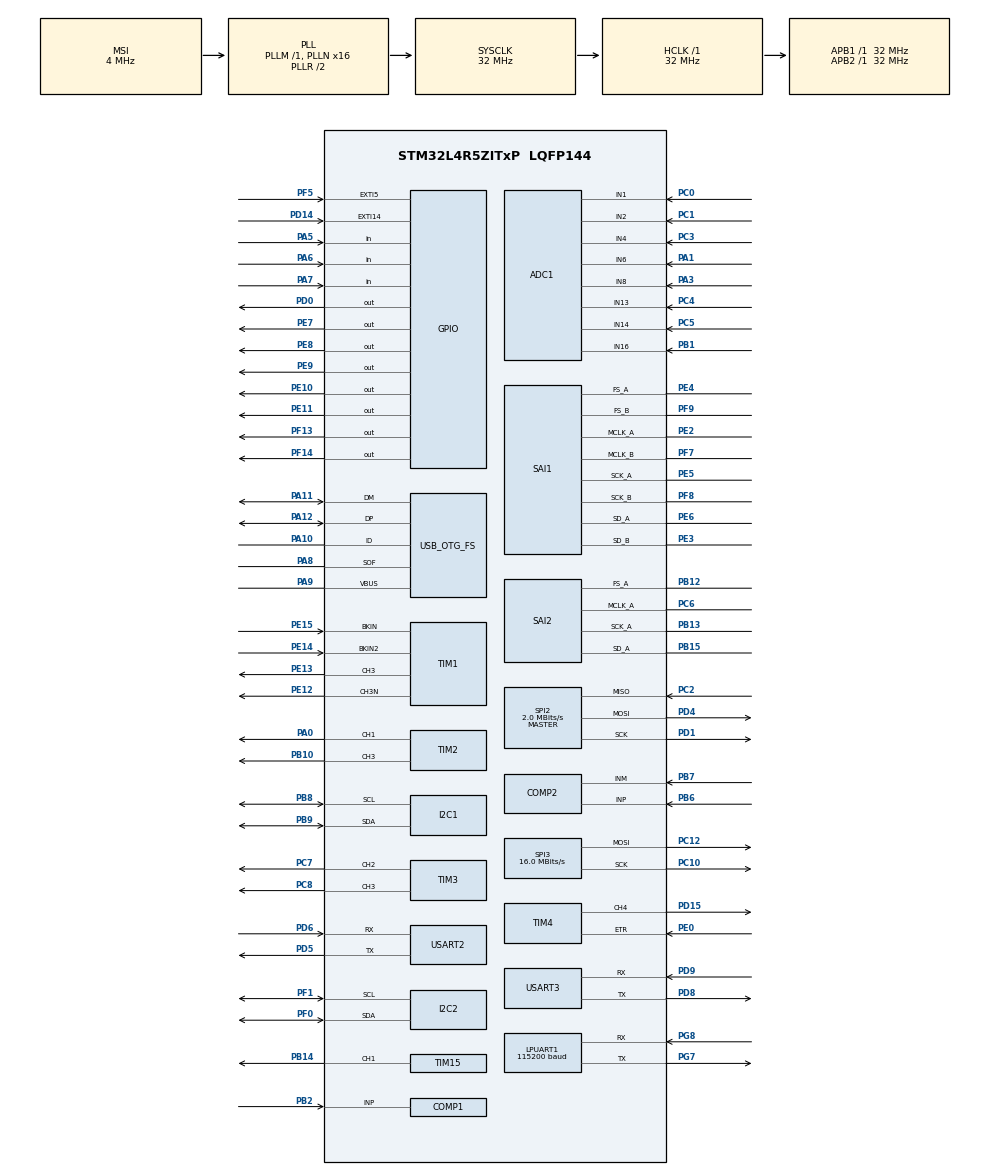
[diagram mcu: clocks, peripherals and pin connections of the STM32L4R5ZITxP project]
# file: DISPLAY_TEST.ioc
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ADC1.Channel-0\#ChannelRegularConversion=ADC_CHANNEL_1
ADC1.NbrOfConversionFlag=1
ADC1.OffsetNumber-0\#ChannelRegularConversion=ADC_OFFSET_NONE
ADC1.Rank-0\#ChannelRegularConversion=1
ADC1.SamplingTime-0\#ChannelRegularConversion=ADC_SAMPLETIME_2CYCLES_5
ADC1.master=1
I2C1.Timing=0x00707CBB
I2C2.Timing=0x00707CBB
LPUART1.BaudRate=115200
LPUART1.WordLength=UART_WORDLENGTH_8B
Mcu.Family=STM32L4
Mcu.Name=STM32L4R5ZITxP
Mcu.Package=LQFP144
NVIC.EXTI15_10_IRQn=true\:0\:0\:false\:false\:true\:true\:true\:true
NVIC.EXTI9_5_IRQn=true\:0\:0\:false\:false\:true\:true\:true\:true
NVIC.PriorityGroup=NVIC_PRIORITYGROUP_4
NVIC.TIM1_TRG_COM_TIM17_IRQn=true\:0\:0\:false\:false\:true\:true\:true\:true
PA0.Signal=S_TIM2_CH1
PA1.Signal=ADCx_IN6
PA10.Mode=OTG/Dual_Role_Device
PA10.Signal=USB_OTG_FS_ID
PA11.Mode=OTG/Dual_Role_Device
PA11.Signal=USB_OTG_FS_DM
PA12.Mode=OTG/Dual_Role_Device
PA12.Signal=USB_OTG_FS_DP
PA13\ (JTMS/SWDIO).Mode=Serial_Wire
PA13\ (JTMS/SWDIO).Signal=SYS_JTMS-SWDIO
PA14\ (JTCK/SWCLK).Mode=Serial_Wire
PA14\ (JTCK/SWCLK).Signal=SYS_JTCK-SWCLK
PA3.Signal=ADCx_IN8
PA4.Signal=SPI1_NSS
PA5.GPIO_PuPd=GPIO_PULLUP
PA5.Signal=GPIO_Input
PA6.GPIO_PuPd=GPIO_PULLUP
PA6.Signal=GPIO_Input
PA7.GPIO_PuPd=GPIO_PULLUP
PA7.Signal=GPIO_Input
PA8.Mode=Activate_SOF_FS
PA8.Signal=USB_OTG_FS_SOF
PA9.Mode=Activate_VBUS
PA9.Signal=USB_OTG_FS_VBUS
PB1.Signal=ADCx_IN16
PB10.Signal=S_TIM2_CH3
PB12.Mode=SAI_A_MasterWithClock
PB12.Signal=SAI2_FS_A
PB13.Mode=SAI_A_MasterWithClock
PB13.Signal=SAI2_SCK_A
PB14.Signal=S_TIM15_CH1
PB15.Mode=SAI_A_MasterWithClock
PB15.Signal=SAI2_SD_A
PB2.Mode=INP
PB2.Signal=COMP1_INP
PB6.Mode=INP
PB6.Signal=COMP2_INP
PB7.Mode=INM
PB7.Signal=COMP2_INM
PB8.GPIO_Pu=GPIO_PULLUP
PB8.Mode=I2C
PB8.Signal=I2C1_SCL
PB9.GPIO_Pu=GPIO_PULLUP
PB9.Mode=I2C
PB9.Signal=I2C1_SDA
PC0.Signal=ADCx_IN1
PC1.Signal=ADCx_IN2
PC10.Mode=TX_Only_Simplex_Unidirect_Master
PC10.Signal=SPI3_SCK
PC11.Signal=SPI3_MISO
PC12.Mode=TX_Only_Simplex_Unidirect_Master
PC12.Signal=SPI3_MOSI
PC13.Mode=SYS_WakeUp1
PC13.Signal=SYS_WKUP2
PC14-OSC32_IN\ (PC14).Mode=LSE-External-Oscillator
PC14-OSC32_IN\ (PC14).Signal=RCC_OSC32_IN
PC15-OSC32_OUT\ (PC15).Mode=LSE-External-Oscillator
PC15-OSC32_OUT\ (PC15).Signal=RCC_OSC32_OUT
PC2.Mode=Full_Duplex_Master
PC2.Signal=SPI2_MISO
PC3.Signal=ADCx_IN4
PC4.Signal=ADCx_IN13
PC5.Signal=ADCx_IN14
PC6.Mode=SAI_A_MasterWithClock
PC6.Signal=SAI2_MCLK_A
PC7.Signal=S_TIM3_CH2
PC8.Signal=S_TIM3_CH3
PC9.Signal=SDMMC1_D1
PD0.PinState=GPIO_PIN_SET
PD0.Signal=GPIO_Output
PD1.Mode=Full_Duplex_Master
PD1.Signal=SPI2_SCK
PD14.GPIO_ModeDefaultEXTI=GPIO_MODE_IT_FALLING
PD14.GPIO_PuPd=GPIO_PULLUP
PD14.Signal=GPXTI14
PD15.Signal=S_TIM4_CH4
PD2.Signal=SDMMC1_CMD
PD4.Mode=Full_Duplex_Master
PD4.Signal=SPI2_MOSI
PD5.Mode=Asynchronous
PD5.Signal=USART2_TX
PD6.Mode=Asynchronous
PD6.Signal=USART2_RX
PD8.Mode=Asynchronous
PD8.Signal=USART3_TX
PD9.Mode=Asynchronous
PD9.Signal=USART3_RX
PE0.Signal=S_TIM4_ETR
PE10.GPIO_PuPd=GPIO_PULLUP
PE10.Signal=GPIO_Output
PE11.GPIO_ModeDefaultOutputPP=GPIO_MODE_OUTPUT_OD
PE11.GPIO_PuPd=GPIO_NOPULL
PE11.PinState=GPIO_PIN_RESET
PE11.Signal=GPIO_Output
PE12.Mode=PWM Generation3 CH3 CH3N
PE12.Signal=TIM1_CH3N
PE13.Signal=S_TIM1_CH3
PE14.Mode=Activate-Break-Input-2
PE14.Signal=TIM1_BKIN2
PE15.Mode=Activate-Break-Input
PE15.Signal=TIM1_BKIN
PE2.Mode=SAI_A_MasterWithClock
PE2.Signal=SAI1_MCLK_A
PE3.Mode=SAI_B_MasterWithClock
PE3.Signal=SAI1_SD_B
PE4.Mode=SAI_A_MasterWithClock
PE4.Signal=SAI1_FS_A
PE5.Mode=SAI_A_MasterWithClock
PE5.Signal=SAI1_SCK_A
PE6.Mode=SAI_A_MasterWithClock
PE6.Signal=SAI1_SD_A
PE7.GPIO_PuPd=GPIO_PULLUP
PE7.Signal=GPIO_Output
PE8.GPIO_PuPd=GPIO_PULLUP
PE8.Signal=GPIO_Output
PE9.GPIO_ModeDefaultOutputPP=GPIO_MODE_OUTPUT_OD
PE9.GPIO_PuPd=GPIO_NOPULL
PE9.PinState=GPIO_PIN_RESET
PE9.Signal=GPIO_Output
PF0.GPIO_Pu=GPIO_NOPULL
PF0.Mode=I2C
PF0.Signal=I2C2_SDA
PF1.GPIO_Pu=GPIO_NOPULL
PF1.Mode=I2C
PF1.Signal=I2C2_SCL
PF13.GPIO_ModeDefaultOutputPP=GPIO_MODE_OUTPUT_OD
PF13.GPIO_PuPd=GPIO_NOPULL
PF13.PinState=GPIO_PIN_RESET
PF13.Signal=GPIO_Output
PF14.GPIO_ModeDefaultOutputPP=GPIO_MODE_OUTPUT_OD
PF14.GPIO_PuPd=GPIO_NOPULL
PF14.PinState=GPIO_PIN_RESET
PF14.Signal=GPIO_Output
PF2.GPIO_Pu=GPIO_PULLUP
PF2.Signal=I2C2_SMBA
PF5.Signal=GPXTI5
PF7.Mode=SAI_B_MasterWithClock
PF7.Signal=SAI1_MCLK_B
PF8.Mode=SAI_B_MasterWithClock
PF8.Signal=SAI1_SCK_B
PF9.Mode=SAI_B_MasterWithClock
PF9.Signal=SAI1_FS_B
PG7.Mode=Asynchronous
PG7.Signal=LPUART1_TX
PG8.Mode=Asynchronous
PG8.Signal=LPUART1_RX
PH0-OSC_IN\ (PH0).Mode=HSE-External-Oscillator
PH0-OSC_IN\ (PH0).Signal=RCC_OSC_IN
PH1-OSC_OUT\ (PH1).Mode=HSE-External-Oscillator
PH1-OSC_OUT\ (PH1).Signal=RCC_OSC_OUT
ProjectManager.HeapSize=0x200
ProjectManager.StackSize=0x400
ProjectManager.TargetToolchain=STM32CubeIDE
RCC.ADCFreq_Value=48000000
RCC.AHBFreq_Value=32000000
RCC.APB1Freq_Value=32000000
RCC.APB1TimFreq_Value=32000000
RCC.APB2Freq_Value=32000000
RCC.APB2TimFreq_Value=32000000
RCC.CortexFreq_Value=32000000
RCC.HCLKFreq_Value=32000000
RCC.HSE_VALUE=8000000
RCC.HSI48_VALUE=48000000
RCC.HSI_VALUE=16000000
RCC.MSI_VALUE=4000000
RCC.PLLN=16
RCC.PLLSAI1N=24
RCC.SYSCLKFreq_VALUE=32000000
RCC.SYSCLKSource=RCC_SYSCLKSOURCE_PLLCLK
RCC.USBFreq_Value=48000000
RCC.VCOOutputFreq_Value=64000000
SAI1.InitProtocol-SAI_A_MasterWithClock=Enable
SAI1.Instance-SAI_A_MasterWithClock=SAI$Index_Block_A
SAI1.Instance-SAI_B_MasterWithClock=SAI$Index_Block_B
SAI1.MClockEnable-SAI_A_MasterWithClock=SAI_MASTERCLOCK_ENABLE
SAI1.MClockEnable-SAI_B_MasterWithClock=SAI_MASTERCLOCK_ENABLE
SAI1.Synchro-SAI_A_MasterWithClock=SAI_ASYNCHRONOUS
SAI1.Synchro-SAI_B_MasterWithClock=SAI_ASYNCHRONOUS
SAI1.VirtualMode-SAI_A_MasterWithClock=VM_MASTER
SAI1.VirtualMode-SAI_B_MasterWithClock=VM_MASTER
SAI1.VirtualProtocol-SAI_A_BASIC=VM_BASIC_PROTOCOL
SAI2.Instance-SAI_A_MasterWithClock=SAI$Index_Block_A
SAI2.MClockEnable-SAI_A_MasterWithClock=SAI_MASTERCLOCK_ENABLE
SAI2.Synchro-SAI_A_MasterWithClock=SAI_ASYNCHRONOUS
SAI2.VirtualMode-SAI_A_MasterWithClock=VM_MASTER
SH.ADCx_IN1.0=ADC1_IN1,IN1-Single-Ended
SH.ADCx_IN13.0=ADC1_IN13,IN13-Single-Ended
SH.ADCx_IN14.0=ADC1_IN14,IN14-Single-Ended
SH.ADCx_IN16.0=ADC1_IN16,IN16-Single-Ended
SH.ADCx_IN2.0=ADC1_IN2,IN2-Single-Ended
SH.ADCx_IN4.0=ADC1_IN4,IN4-Single-Ended
SH.ADCx_IN6.0=ADC1_IN6,IN6-Single-Ended
SH.ADCx_IN8.0=ADC1_IN8,IN8-Single-Ended
SH.S_TIM15_CH1.0=TIM15_CH1,PWM Generation1 CH1
SH.S_TIM1_CH3.0=TIM1_CH3,PWM Generation3 CH3 CH3N
SH.S_TIM2_CH1.0=TIM2_CH1,PWM Generation1 CH1
SH.S_TIM2_CH3.0=TIM2_CH3,PWM Generation3 CH3
SH.S_TIM3_CH2.0=TIM3_CH2,PWM Generation2 CH2
SH.S_TIM3_CH3.0=TIM3_CH3,PWM Generation3 CH3
SH.S_TIM4_CH4.0=TIM4_CH4,PWM Generation4 CH4
SH.S_TIM4_ETR.0=TIM4_ETR,ETR-as-clearing-source
SPI2.BaudRatePrescaler=SPI_BAUDRATEPRESCALER_16
SPI2.CalculateBaudRate=2.0 MBits/s
SPI2.DataSize=SPI_DATASIZE_8BIT
SPI2.Direction=SPI_DIRECTION_2LINES
SPI2.Mode=SPI_MODE_MASTER
SPI2.VirtualType=VM_MASTER
SPI3.CalculateBaudRate=16.0 MBits/s
SPI3.DataSize=SPI_DATASIZE_8BIT
SPI3.Direction=SPI_DIRECTION_2LINES
SPI3.Mode=SPI_MODE_MASTER
SPI3.VirtualType=VM_MASTER
TIM1.Channel-PWM\ Generation3\ CH3\ CH3N=TIM_CHANNEL_3
TIM15.Channel-PWM\ Generation1\ CH1=TIM_CHANNEL_1
TIM17.Channel=TIM_CHANNEL_1
TIM17.Prescaler=2441
TIM2.Channel-PWM\ Generation1\ CH1=TIM_CHANNEL_1
TIM2.Channel-PWM\ Generation3\ CH3=TIM_CHANNEL_3
TIM3.Channel-PWM\ Generation2\ CH2=TIM_CHANNEL_2
TIM3.Channel-PWM\ Generation3\ CH3=TIM_CHANNEL_3
TIM4.Channel-PWM\ Generation4\ CH4=TIM_CHANNEL_4
USART2.VirtualMode-Asynchronous=VM_ASYNC
USART3.VirtualMode-Asynchronous=VM_ASYNC
VP_COMP1_VS_VREFINT.Mode=VREFINT
VP_SAI1_VP_$IpInstance_SAIA_SAI_BASIC.Mode=SAI_A_BASIC
VP_TIM17_VS_ClockSourceINT.Mode=Enable_Timer
VP_TIM17_VS_no_output1.Mode=Output Compare1 No Output
VP_TIM3_VS_ClockSourceINT.Mode=Internal
board=NUCLEO-L4R5ZI-P

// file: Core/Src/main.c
/* USER CODE BEGIN Header */
/**
 ******************************************************************************
 * @file           : main.c
 * @brief          : Main program body
 ******************************************************************************
 * @attention
 *
 * Copyright (c) 2024 STMicroelectronics.
 * All rights reserved.
 *
 * This software is licensed under terms that can be found in the LICENSE file
 * in the root directory of this software component.
 * If no LICENSE file comes with this software, it is provided AS-IS.
 *
 ******************************************************************************
 */
/* USER CODE END Header */
#include "main.h"

/* USER CODE BEGIN Includes */
#include "TempHumSensor.h"
#include "lcd.h"
#include "lora_sx1276.h"
#include "strain.h"
/* USER CODE END Includes */

ADC_HandleTypeDef hadc1;

COMP_HandleTypeDef hcomp1;
COMP_HandleTypeDef hcomp2;

I2C_HandleTypeDef hi2c1;
I2C_HandleTypeDef hi2c2;

UART_HandleTypeDef hlpuart1;
UART_HandleTypeDef huart2;
UART_HandleTypeDef huart3;

SAI_HandleTypeDef hsai_BlockB1;
SAI_HandleTypeDef hsai_BlockA1;
SAI_HandleTypeDef hsai_BlockA2;

SPI_HandleTypeDef hspi2;
SPI_HandleTypeDef hspi3;

TIM_HandleTypeDef htim1;
TIM_HandleTypeDef htim2;
TIM_HandleTypeDef htim3;
TIM_HandleTypeDef htim4;
TIM_HandleTypeDef htim15;
TIM_HandleTypeDef htim17;

/* USER CODE BEGIN PV */
lora_sx1276 lora;
uint8_t DISPLAY_TIMER_TRIGGERED;
// When 'D' is selected
uint8_t KeyPadSelect = 0;
uint8_t LoRaRecieve = 0;
extern uint8_t age;

// struct gps_data {
//	float longitude;
//	float latitude;
// };

struct arm_to_base {
  //	struct gps_data data;
  float velocity;
  float distance;
  int heartrate;
  int steps;
};

// Or were we sending height and weight over LoRa???
struct base_to_arm {
  uint8_t buzz;
};
/* USER CODE END PV */

void SystemClock_Config(void);
void PeriphCommonClock_Config(void);
static void MX_GPIO_Init(void);
static void MX_ADC1_Init(void);
static void MX_COMP1_Init(void);
static void MX_COMP2_Init(void);
static void MX_I2C1_Init(void);
static void MX_I2C2_Init(void);
static void MX_LPUART1_UART_Init(void);
static void MX_USART2_UART_Init(void);
static void MX_USART3_UART_Init(void);
static void MX_SAI1_Init(void);
static void MX_SAI2_Init(void);
static void MX_SPI3_Init(void);
static void MX_TIM1_Init(void);
static void MX_TIM2_Init(void);
static void MX_TIM3_Init(void);
static void MX_TIM4_Init(void);
static void MX_TIM15_Init(void);
static void MX_USB_OTG_FS_USB_Init(void);
static void MX_TIM17_Init(void);
static void MX_SPI2_Init(void);

int main(void) {
  /* USER CODE BEGIN 1 */
  CoreDebug->DEMCR |= CoreDebug_DEMCR_TRCENA_Msk;  // Enable DWT
  DWT->CYCCNT = 0;                                 // Clear counter
  DWT->CTRL = DWT_CTRL_CYCCNTENA_Msk;              // Enable counter
  /* USER CODE END 1 */

  /* MCU Configuration--------------------------------------------------------*/

  /* Reset of all peripherals, Initializes the Flash interface and the Systick.
   */
  HAL_Init();

  /* Configure the system clock */
  SystemClock_Config();

  /* Configure the peripherals common clocks */
  PeriphCommonClock_Config();

  /* Initialize all configured peripherals */
  MX_GPIO_Init();
  MX_ADC1_Init();
  MX_COMP1_Init();
  MX_COMP2_Init();
  MX_I2C1_Init();
  MX_I2C2_Init();
  MX_LPUART1_UART_Init();
  MX_USART2_UART_Init();
  MX_USART3_UART_Init();
  MX_SAI1_Init();
  MX_SAI2_Init();
  MX_SPI3_Init();
  MX_TIM1_Init();
  MX_TIM2_Init();
  MX_TIM3_Init();
  MX_TIM4_Init();
  MX_TIM15_Init();
  MX_USB_OTG_FS_USB_Init();
  MX_TIM17_Init();
  MX_SPI2_Init();
  /* USER CODE BEGIN 2 */
  HAL_TIM_PWM_Start(&htim3, TIM_CHANNEL_3);

  // Initialize LoRa
  uint8_t res = lora_init(&lora, &hspi2, GPIOD, GPIO_PIN_0,
                          LORA_BASE_FREQUENCY_US + FREQ_OFFSET);

  // If LoRa init fails, just keep trying until it works
  while (res != LORA_OK) {
    // Initialization failed
    HAL_Delay(100);
    res = lora_init(&lora, &hspi2, GPIOD, GPIO_PIN_0,
                    LORA_BASE_FREQUENCY_US + FREQ_OFFSET);
  }
  // Initializing the display takes a minute,
  // because it writes black to every pixal on the screen
  LCD_init();
  // Write to LoRa register to pull DIO_0 line high when
  // a packet is recieved
  lora_enable_interrupt_rx_done(&lora);
  // Write to LoRa register to recieve packets
  lora_mode_receive_continuous(&lora);
  JOYSTICK_INIT(hi2c1);
  // Temp/Humid
  TempHum_t data;
  initTempHumSensor(&hi2c2);
  /* USER CODE END 2 */

  /* Infinite loop */
  /* USER CODE BEGIN WHILE */

  // current_viewport:
  // determines what screen state you are on
  // 0 = runner view
  // 1 = player 1 view
  // 2 = weight and age input view
  uint8_t current_viewport = 0;

  // Update display when true
  DISPLAY_TIMER_TRIGGERED = 0;
  // Start timer for updating display
  HAL_TIM_Base_Start_IT(&htim17);

  // Set this pin ('D' on keypad) low for interrupt
  HAL_GPIO_WritePin(GPIOF, GPIO_PIN_13, 0);

  // Zero struct data
  struct arm_to_base armband_data = {0, 0, 0, 0};
  struct arm_to_base TEMPCOPY = {0, 0, 0, 0};
  struct base_to_arm buzzer = {0};

  // Fill dimensions for clearing display
  uint16_t player_data_fill_height = 170;
  uint16_t player_data_fill_bottom = 50;

  // Buffer for player data display
  char player_write_buffer[128];
  // Buffer for stamina label display
  char stamina_write_buffer[16];
  // Buffer for stamina data display
  char stamina_data_write_buffer[16];
  // Buffer for temp/humid display
  char temp_humid_write_buffer[64];
  // Buffer for LoRa data
  char buffer[128];

  int heartrate;
  int stepcount;

  uint8_t buzzing = 0;
  uint8_t wait = 1;
  float distance = 0;
  // Only buzz once when someone passes the threshold
  // Will reset when user drops back below the threshold
  uint8_t buzz_triggered = 0;
  while (1) {
    /* USER CODE END WHILE */

    /* USER CODE BEGIN 3 */

    // STATE MACHINE HERE
    // STATES SO FAR: INPUT WEIGHT, DISPLAY RUNNER DATA
    // Joystick allows user to switch between states

    uint8_t lr = threshold();
    if (lr == 2) {
      current_viewport = (current_viewport == 2) ? 2 : 1;
      // Clear dirty parts of the screen
      LCD_Fill(0, 5, 240, player_data_fill_height, C_BLACK);
      LCD_Fill(0, player_data_fill_bottom, 240, 320, C_BLACK);
      // allows for instant transition
      DISPLAY_TIMER_TRIGGERED = 1;
    }
    // Toggle current_viewport when joystick left
    else if (lr == 1) {
      current_viewport = (current_viewport == 2) ? 2 : 0;
      // Clear dirty parts of the screen
      LCD_Fill(0, 5, 240, player_data_fill_height, C_BLACK);
      LCD_Fill(0, player_data_fill_bottom, 240, 320, C_BLACK);
      // allows for instant transition
      DISPLAY_TIMER_TRIGGERED = 1;
    }

    // Turn buzzing off if it meets the proper conditions
    if (DISPLAY_TIMER_TRIGGERED == 1 && buzzing) {
      if (wait == 0) {
        TIM3->CCR3 = 0;
        buzzing = 0;
        wait = 1;
      } else {
        wait = 0;
      }
    }

    if (LoRaRecieve == 1) {
      // Get data from LoRa
      lora_receive_packet_blocking(&lora, buffer, sizeof(buffer), 10000, &res);
      // memcpy(&armband_data, &buffer, sizeof(armband_data));
      // This is for discarding packets that are not ours
      memcpy(&TEMPCOPY, &buffer, sizeof(TEMPCOPY));
      if (TEMPCOPY.heartrate > 1 && TEMPCOPY.heartrate < 300 && TEMPCOPY.distance < 500 && TEMPCOPY.velocity < 100) {
        armband_data = TEMPCOPY;
        distance += armband_data.distance;
        // Update values for Stamina calculations
        input_data(armband_data.heartrate, armband_data.velocity);
      }

      //		  	  if (res != LORA_OK) {
      //		  		  // Receive failed
      //		  	  }

      if (heartRateHigh(armband_data.heartrate, age) ||
          heartRateLow(armband_data.heartrate, age)) {
        lora_send_packet(&lora, &buzzer, 1);
        // res = lora_send_packet(&lora, &buzzer, 1);
      }

      // Conditions to set buzz at base station
      if (get_strain_factor() < 50 && get_strain_factor() > 0) {
        if (!buzz_triggered) {
          TIM3->CCR3 = 15000;
          buzzing = 1;
          buzz_triggered = 1;
        }
      } else {
        buzz_triggered = 0;
      }

      // Writing register on LoRa to enter receiving mode again
      // May not be necessary
      lora_mode_receive_continuous(&lora);

      // Checking if there is a packet waiting to be read. This should never
      // trigger, but if it does, even by just noise, we should be set
      if (!lora_is_packet_available(&lora)) LoRaRecieve = 0;
    }

    // HOME SCREEN / RUNNER VIEW
    // Updates every 5 seconds
    if (current_viewport == 0 && DISPLAY_TIMER_TRIGGERED == 1) {
      UG_FontSetTransparency(1);
      data = get_temp_hum();
      // Clear current temp/humid data
      LCD_Fill(80, 5, 240, 120, C_BLACK);
      // Print temp/humid data
      snprintf(temp_humid_write_buffer, sizeof(temp_humid_write_buffer),
               "Temp: %.3f\nHumid: %.3f", data.temp, data.hum);
      LCD_PutStr(5, 5, temp_humid_write_buffer, DEFAULT_FONT, C_WHITE, C_BLACK);

      // Stamina stuff below
      // Erase previous stamina label and data
      LCD_PutStr(5, 260, stamina_write_buffer, DEFAULT_FONT, C_BLACK, C_BLACK);
      LCD_PutStr(150, 288, stamina_data_write_buffer, DEFAULT_FONT, C_BLACK,
                 C_BLACK);
      // Add label to buffer
      snprintf(stamina_write_buffer, sizeof(stamina_write_buffer),
               "\nR1 Stamina: ");

      float stamina = get_strain_factor();
      // Add value to a second buffer
      snprintf(stamina_data_write_buffer, sizeof(stamina_data_write_buffer),
               "%.3f", stamina);
      // Write field buffer
      LCD_PutStr(5, 260, stamina_write_buffer, DEFAULT_FONT, C_WHITE, C_BLACK);
      // Determine color of stamina based on stamina value
      uint16_t stamina_color;
      if (stamina == -1 || stamina < 50) {
        stamina_color = 0b0000011111100000;  // RED
      } else if (stamina > 100) {
        stamina_color = 0b0000011111111111;  // YELLOW
      } else {
        stamina_color = 0b0000000000011111;  // GREEN
      }
      // Write value buffer
      LCD_PutStr(150, 288, stamina_data_write_buffer, DEFAULT_FONT,
                 stamina_color, C_BLACK);

      // Reset display refresh
      DISPLAY_TIMER_TRIGGERED = 0;
    }
    // Enter age/weight input
    if (current_viewport != 2 && KeyPadSelect) {
      current_viewport = 2;
    }

    // Runner stats screen
    if (current_viewport == 1 && DISPLAY_TIMER_TRIGGERED == 1) {
      UG_FontSetTransparency(1);
      // Overwrite the previous data in black text to erase
      LCD_PutStr(5, 5, player_write_buffer, DEFAULT_FONT, C_BLACK, C_BLACK);
      LCD_PutStr(5, 260, stamina_write_buffer, DEFAULT_FONT, C_BLACK, C_BLACK);
      LCD_PutStr(120, 288, stamina_data_write_buffer, DEFAULT_FONT, C_BLACK,
                 C_BLACK);

      // Read in new runner data
      snprintf(player_write_buffer, sizeof(player_write_buffer),
               "R1 Statistics\n \nVelocity: %.3f\nHeart Rate: %d\nDistance: "
               "%.3f\nStep Count: %d",
               armband_data.velocity, armband_data.heartrate, distance, armband_data.steps);
      // Write runner data to display
      LCD_PutStr(5, 5, player_write_buffer, DEFAULT_FONT, C_WHITE, C_BLACK);
      // Read in runner stamina label
      snprintf(stamina_write_buffer, sizeof(stamina_write_buffer),
               "\nStamina: ");
      // Display runner stamina label
      LCD_PutStr(5, 260, stamina_write_buffer, DEFAULT_FONT, C_WHITE, C_BLACK);
      // Get stamina data and write to display
      float stamina = get_strain_factor();
      snprintf(stamina_data_write_buffer, sizeof(stamina_data_write_buffer),
               "%.3f", stamina);
      uint16_t stamina_color;
      if (stamina == -1 || stamina < 50) {
        stamina_color = 0b0000011111100000;  // RED
      } else if (stamina > 100) {
        stamina_color = 0b0000011111111111;  // YELLOW
      } else {
        stamina_color = 0b0000000000011111;  // GREEN
      }
      // Write stamina data
      LCD_PutStr(120, 288, stamina_data_write_buffer, DEFAULT_FONT,
                 stamina_color, C_BLACK);
      DISPLAY_TIMER_TRIGGERED = 0;
    }

    // WEIGHT AND AGE INPUT
    if (current_viewport == 2) {
      LCD_Fill(5, 5, 240, player_data_fill_height, C_BLACK);
      LCD_Fill(5, player_data_fill_bottom, 240, 320, C_BLACK);
      // Account for debounce
      while (HAL_GPIO_ReadPin(GPIOD, GPIO_PIN_14) == GPIO_PIN_RESET) {
      }
      keypad_init();
      // Entire data input process
      running();
      // Send age for stamina
      init_analytics(age);
      KeyPadSelect = 0;
      // Go back to runner screen
      current_viewport = 1;
      LCD_Fill(5, 5, 160, 40, C_BLACK);
      DISPLAY_TIMER_TRIGGERED = 1;
      // Listen to 'D' again
      HAL_GPIO_WritePin(GPIOF, GPIO_PIN_13, 0);
    }
    // 0b1111100000000000 = Blue
    // 0b0000011111100000 = Red
    // 0b0000000000011111 = Green
  }
  /* USER CODE END 3 */
}

void SystemClock_Config(void) {
  RCC_OscInitTypeDef RCC_OscInitStruct = {0};
  RCC_ClkInitTypeDef RCC_ClkInitStruct = {0};

  /** Configure the main internal regulator output voltage
   */
  if (HAL_PWREx_ControlVoltageScaling(PWR_REGULATOR_VOLTAGE_SCALE1) != HAL_OK) {
    Error_Handler();
  }

  /** Configure LSE Drive Capability
   */
  HAL_PWR_EnableBkUpAccess();
  __HAL_RCC_LSEDRIVE_CONFIG(RCC_LSEDRIVE_LOW);

  /** Initializes the RCC Oscillators according to the specified parameters
   * in the RCC_OscInitTypeDef structure.
   */
  RCC_OscInitStruct.OscillatorType =
      RCC_OSCILLATORTYPE_LSE | RCC_OSCILLATORTYPE_MSI;
  RCC_OscInitStruct.LSEState = RCC_LSE_ON;
  RCC_OscInitStruct.MSIState = RCC_MSI_ON;
  RCC_OscInitStruct.MSICalibrationValue = 0;
  RCC_OscInitStruct.MSIClockRange = RCC_MSIRANGE_6;
  RCC_OscInitStruct.PLL.PLLState = RCC_PLL_ON;
  RCC_OscInitStruct.PLL.PLLSource = RCC_PLLSOURCE_MSI;
  RCC_OscInitStruct.PLL.PLLM = 1;
  RCC_OscInitStruct.PLL.PLLN = 16;
  RCC_OscInitStruct.PLL.PLLP = RCC_PLLP_DIV2;
  RCC_OscInitStruct.PLL.PLLQ = RCC_PLLQ_DIV2;
  RCC_OscInitStruct.PLL.PLLR = RCC_PLLR_DIV2;
  if (HAL_RCC_OscConfig(&RCC_OscInitStruct) != HAL_OK) {
    Error_Handler();
  }

  /** Initializes the CPU, AHB and APB buses clocks
   */
  RCC_ClkInitStruct.ClockType = RCC_CLOCKTYPE_HCLK | RCC_CLOCKTYPE_SYSCLK |
                                RCC_CLOCKTYPE_PCLK1 | RCC_CLOCKTYPE_PCLK2;
  RCC_ClkInitStruct.SYSCLKSource = RCC_SYSCLKSOURCE_PLLCLK;
  RCC_ClkInitStruct.AHBCLKDivider = RCC_SYSCLK_DIV1;
  RCC_ClkInitStruct.APB1CLKDivider = RCC_HCLK_DIV1;
  RCC_ClkInitStruct.APB2CLKDivider = RCC_HCLK_DIV1;

  if (HAL_RCC_ClockConfig(&RCC_ClkInitStruct, FLASH_LATENCY_1) != HAL_OK) {
    Error_Handler();
  }

  /** Enable MSI Auto calibration
   */
  HAL_RCCEx_EnableMSIPLLMode();
}

void PeriphCommonClock_Config(void) {
  RCC_PeriphCLKInitTypeDef PeriphClkInit = {0};

  /** Initializes the peripherals clock
   */
  PeriphClkInit.PeriphClockSelection = RCC_PERIPHCLK_SAI1 | RCC_PERIPHCLK_SAI2 |
                                       RCC_PERIPHCLK_USB | RCC_PERIPHCLK_ADC;
  PeriphClkInit.Sai1ClockSelection = RCC_SAI1CLKSOURCE_PLLSAI1;
  PeriphClkInit.Sai2ClockSelection = RCC_SAI2CLKSOURCE_PLLSAI1;
  PeriphClkInit.AdcClockSelection = RCC_ADCCLKSOURCE_PLLSAI1;
  PeriphClkInit.UsbClockSelection = RCC_USBCLKSOURCE_PLLSAI1;
  PeriphClkInit.PLLSAI1.PLLSAI1Source = RCC_PLLSOURCE_MSI;
  PeriphClkInit.PLLSAI1.PLLSAI1M = 1;
  PeriphClkInit.PLLSAI1.PLLSAI1N = 24;
  PeriphClkInit.PLLSAI1.PLLSAI1P = RCC_PLLP_DIV2;
  PeriphClkInit.PLLSAI1.PLLSAI1Q = RCC_PLLQ_DIV2;
  PeriphClkInit.PLLSAI1.PLLSAI1R = RCC_PLLR_DIV2;
  PeriphClkInit.PLLSAI1.PLLSAI1ClockOut =
      RCC_PLLSAI1_SAI1CLK | RCC_PLLSAI1_48M2CLK | RCC_PLLSAI1_ADC1CLK;
  if (HAL_RCCEx_PeriphCLKConfig(&PeriphClkInit) != HAL_OK) {
    Error_Handler();
  }
}

static void MX_ADC1_Init(void) {

  ADC_ChannelConfTypeDef sConfig = {0};

  /** Common config
   */
  hadc1.Instance = ADC1;
  hadc1.Init.ClockPrescaler = ADC_CLOCK_ASYNC_DIV1;
  hadc1.Init.Resolution = ADC_RESOLUTION_12B;
  hadc1.Init.DataAlign = ADC_DATAALIGN_RIGHT;
  hadc1.Init.ScanConvMode = ADC_SCAN_DISABLE;
  hadc1.Init.EOCSelection = ADC_EOC_SINGLE_CONV;
  hadc1.Init.LowPowerAutoWait = DISABLE;
  hadc1.Init.ContinuousConvMode = DISABLE;
  hadc1.Init.NbrOfConversion = 1;
  hadc1.Init.DiscontinuousConvMode = DISABLE;
  hadc1.Init.ExternalTrigConv = ADC_SOFTWARE_START;
  hadc1.Init.ExternalTrigConvEdge = ADC_EXTERNALTRIGCONVEDGE_NONE;
  hadc1.Init.DMAContinuousRequests = DISABLE;
  hadc1.Init.Overrun = ADC_OVR_DATA_PRESERVED;
  hadc1.Init.OversamplingMode = DISABLE;
  if (HAL_ADC_Init(&hadc1) != HAL_OK) {
    Error_Handler();
  }

  /** Configure Regular Channel
   */
  sConfig.Channel = ADC_CHANNEL_1;
  sConfig.Rank = ADC_REGULAR_RANK_1;
  sConfig.SamplingTime = ADC_SAMPLETIME_2CYCLES_5;
  sConfig.SingleDiff = ADC_SINGLE_ENDED;
  sConfig.OffsetNumber = ADC_OFFSET_NONE;
  sConfig.Offset = 0;
  if (HAL_ADC_ConfigChannel(&hadc1, &sConfig) != HAL_OK) {
    Error_Handler();
  }
}

static void MX_COMP1_Init(void) {

  hcomp1.Instance = COMP1;
  hcomp1.Init.InvertingInput = COMP_INPUT_MINUS_VREFINT;
  hcomp1.Init.NonInvertingInput = COMP_INPUT_PLUS_IO2;
  hcomp1.Init.OutputPol = COMP_OUTPUTPOL_NONINVERTED;
  hcomp1.Init.Hysteresis = COMP_HYSTERESIS_NONE;
  hcomp1.Init.BlankingSrce = COMP_BLANKINGSRC_NONE;
  hcomp1.Init.Mode = COMP_POWERMODE_HIGHSPEED;
  hcomp1.Init.WindowMode = COMP_WINDOWMODE_DISABLE;
  hcomp1.Init.TriggerMode = COMP_TRIGGERMODE_NONE;
  if (HAL_COMP_Init(&hcomp1) != HAL_OK) {
    Error_Handler();
  }
}

static void MX_COMP2_Init(void) {

  hcomp2.Instance = COMP2;
  hcomp2.Init.InvertingInput = COMP_INPUT_MINUS_IO2;
  hcomp2.Init.NonInvertingInput = COMP_INPUT_PLUS_IO2;
  hcomp2.Init.OutputPol = COMP_OUTPUTPOL_NONINVERTED;
  hcomp2.Init.Hysteresis = COMP_HYSTERESIS_NONE;
  hcomp2.Init.BlankingSrce = COMP_BLANKINGSRC_NONE;
  hcomp2.Init.Mode = COMP_POWERMODE_HIGHSPEED;
  hcomp2.Init.WindowMode = COMP_WINDOWMODE_DISABLE;
  hcomp2.Init.TriggerMode = COMP_TRIGGERMODE_NONE;
  if (HAL_COMP_Init(&hcomp2) != HAL_OK) {
    Error_Handler();
  }
}

static void MX_I2C1_Init(void) {

  hi2c1.Instance = I2C1;
  hi2c1.Init.Timing = 0x00707CBB;
  hi2c1.Init.OwnAddress1 = 0;
  hi2c1.Init.AddressingMode = I2C_ADDRESSINGMODE_7BIT;
  hi2c1.Init.DualAddressMode = I2C_DUALADDRESS_DISABLE;
  hi2c1.Init.OwnAddress2 = 0;
  hi2c1.Init.OwnAddress2Masks = I2C_OA2_NOMASK;
  hi2c1.Init.GeneralCallMode = I2C_GENERALCALL_DISABLE;
  hi2c1.Init.NoStretchMode = I2C_NOSTRETCH_DISABLE;
  if (HAL_I2C_Init(&hi2c1) != HAL_OK) {
    Error_Handler();
  }

  /** Configure Analogue filter
   */
  if (HAL_I2CEx_ConfigAnalogFilter(&hi2c1, I2C_ANALOGFILTER_ENABLE) != HAL_OK) {
    Error_Handler();
  }

  /** Configure Digital filter
   */
  if (HAL_I2CEx_ConfigDigitalFilter(&hi2c1, 0) != HAL_OK) {
    Error_Handler();
  }
}

static void MX_I2C2_Init(void) {

  hi2c2.Instance = I2C2;
  hi2c2.Init.Timing = 0x00707CBB;
  hi2c2.Init.OwnAddress1 = 0;
  hi2c2.Init.AddressingMode = I2C_ADDRESSINGMODE_7BIT;
  hi2c2.Init.DualAddressMode = I2C_DUALADDRESS_DISABLE;
  hi2c2.Init.OwnAddress2 = 0;
  hi2c2.Init.OwnAddress2Masks = I2C_OA2_NOMASK;
  hi2c2.Init.GeneralCallMode = I2C_GENERALCALL_DISABLE;
  hi2c2.Init.NoStretchMode = I2C_NOSTRETCH_DISABLE;
  if (HAL_I2C_Init(&hi2c2) != HAL_OK) {
    Error_Handler();
  }

  /** Configure Analogue filter
   */
  if (HAL_I2CEx_ConfigAnalogFilter(&hi2c2, I2C_ANALOGFILTER_ENABLE) != HAL_OK) {
    Error_Handler();
  }

  /** Configure Digital filter
   */
  if (HAL_I2CEx_ConfigDigitalFilter(&hi2c2, 0) != HAL_OK) {
    Error_Handler();
  }
}

static void MX_LPUART1_UART_Init(void) {

  hlpuart1.Instance = LPUART1;
  hlpuart1.Init.BaudRate = 115200;
  hlpuart1.Init.WordLength = UART_WORDLENGTH_8B;
  hlpuart1.Init.StopBits = UART_STOPBITS_1;
  hlpuart1.Init.Parity = UART_PARITY_NONE;
  hlpuart1.Init.Mode = UART_MODE_TX_RX;
  hlpuart1.Init.HwFlowCtl = UART_HWCONTROL_NONE;
  hlpuart1.Init.OneBitSampling = UART_ONE_BIT_SAMPLE_DISABLE;
  hlpuart1.Init.ClockPrescaler = UART_PRESCALER_DIV1;
  hlpuart1.AdvancedInit.AdvFeatureInit = UART_ADVFEATURE_NO_INIT;
  hlpuart1.FifoMode = UART_FIFOMODE_DISABLE;
  if (HAL_UART_Init(&hlpuart1) != HAL_OK) {
    Error_Handler();
  }
  if (HAL_UARTEx_SetTxFifoThreshold(&hlpuart1, UART_TXFIFO_THRESHOLD_1_8) !=
      HAL_OK) {
    Error_Handler();
  }
  if (HAL_UARTEx_SetRxFifoThreshold(&hlpuart1, UART_RXFIFO_THRESHOLD_1_8) !=
      HAL_OK) {
    Error_Handler();
  }
  if (HAL_UARTEx_DisableFifoMode(&hlpuart1) != HAL_OK) {
    Error_Handler();
  }
}

static void MX_USART2_UART_Init(void) {

  huart2.Instance = USART2;
  huart2.Init.BaudRate = 115200;
  huart2.Init.WordLength = UART_WORDLENGTH_8B;
  huart2.Init.StopBits = UART_STOPBITS_1;
  huart2.Init.Parity = UART_PARITY_NONE;
  huart2.Init.Mode = UART_MODE_TX_RX;
  huart2.Init.HwFlowCtl = UART_HWCONTROL_NONE;
  huart2.Init.OverSampling = UART_OVERSAMPLING_16;
  huart2.Init.OneBitSampling = UART_ONE_BIT_SAMPLE_DISABLE;
  huart2.Init.ClockPrescaler = UART_PRESCALER_DIV1;
  huart2.AdvancedInit.AdvFeatureInit = UART_ADVFEATURE_NO_INIT;
  if (HAL_UART_Init(&huart2) != HAL_OK) {
    Error_Handler();
  }
  if (HAL_UARTEx_SetTxFifoThreshold(&huart2, UART_TXFIFO_THRESHOLD_1_8) !=
      HAL_OK) {
    Error_Handler();
  }
  if (HAL_UARTEx_SetRxFifoThreshold(&huart2, UART_RXFIFO_THRESHOLD_1_8) !=
      HAL_OK) {
    Error_Handler();
  }
  if (HAL_UARTEx_DisableFifoMode(&huart2) != HAL_OK) {
    Error_Handler();
  }
}

static void MX_USART3_UART_Init(void) {

  huart3.Instance = USART3;
  huart3.Init.BaudRate = 115200;
  huart3.Init.WordLength = UART_WORDLENGTH_8B;
  huart3.Init.StopBits = UART_STOPBITS_1;
  huart3.Init.Parity = UART_PARITY_NONE;
  huart3.Init.Mode = UART_MODE_TX_RX;
  huart3.Init.HwFlowCtl = UART_HWCONTROL_NONE;
  huart3.Init.OverSampling = UART_OVERSAMPLING_16;
  huart3.Init.OneBitSampling = UART_ONE_BIT_SAMPLE_DISABLE;
  huart3.Init.ClockPrescaler = UART_PRESCALER_DIV1;
  huart3.AdvancedInit.AdvFeatureInit = UART_ADVFEATURE_NO_INIT;
  if (HAL_UART_Init(&huart3) != HAL_OK) {
    Error_Handler();
  }
  if (HAL_UARTEx_SetTxFifoThreshold(&huart3, UART_TXFIFO_THRESHOLD_1_8) !=
      HAL_OK) {
    Error_Handler();
  }
  if (HAL_UARTEx_SetRxFifoThreshold(&huart3, UART_RXFIFO_THRESHOLD_1_8) !=
      HAL_OK) {
    Error_Handler();
  }
  if (HAL_UARTEx_DisableFifoMode(&huart3) != HAL_OK) {
    Error_Handler();
  }
}

static void MX_SAI1_Init(void) {

  hsai_BlockB1.Instance = SAI1_Block_B;
  hsai_BlockB1.Init.Protocol = SAI_FREE_PROTOCOL;
  hsai_BlockB1.Init.AudioMode = SAI_MODEMASTER_TX;
  hsai_BlockB1.Init.DataSize = SAI_DATASIZE_8;
  hsai_BlockB1.Init.FirstBit = SAI_FIRSTBIT_MSB;
  hsai_BlockB1.Init.ClockStrobing = SAI_CLOCKSTROBING_FALLINGEDGE;
  hsai_BlockB1.Init.Synchro = SAI_ASYNCHRONOUS;
  hsai_BlockB1.Init.OutputDrive = SAI_OUTPUTDRIVE_DISABLE;
  hsai_BlockB1.Init.NoDivider = SAI_MASTERDIVIDER_ENABLE;
  hsai_BlockB1.Init.MckOverSampling = SAI_MCK_OVERSAMPLING_DISABLE;
  hsai_BlockB1.Init.FIFOThreshold = SAI_FIFOTHRESHOLD_EMPTY;
  hsai_BlockB1.Init.AudioFrequency = SAI_AUDIO_FREQUENCY_192K;
  hsai_BlockB1.Init.SynchroExt = SAI_SYNCEXT_DISABLE;
  hsai_BlockB1.Init.MonoStereoMode = SAI_STEREOMODE;
  hsai_BlockB1.Init.CompandingMode = SAI_NOCOMPANDING;
  hsai_BlockB1.Init.TriState = SAI_OUTPUT_NOTRELEASED;
  hsai_BlockB1.Init.PdmInit.Activation = DISABLE;
  hsai_BlockB1.Init.PdmInit.MicPairsNbr = 0;
  hsai_BlockB1.Init.PdmInit.ClockEnable = SAI_PDM_CLOCK1_ENABLE;
  hsai_BlockB1.FrameInit.FrameLength = 8;
  hsai_BlockB1.FrameInit.ActiveFrameLength = 1;
  hsai_BlockB1.FrameInit.FSDefinition = SAI_FS_STARTFRAME;
  hsai_BlockB1.FrameInit.FSPolarity = SAI_FS_ACTIVE_LOW;
  hsai_BlockB1.FrameInit.FSOffset = SAI_FS_FIRSTBIT;
  hsai_BlockB1.SlotInit.FirstBitOffset = 0;
  hsai_BlockB1.SlotInit.SlotSize = SAI_SLOTSIZE_DATASIZE;
  hsai_BlockB1.SlotInit.SlotNumber = 1;
  hsai_BlockB1.SlotInit.SlotActive = 0x00000000;
  if (HAL_SAI_Init(&hsai_BlockB1) != HAL_OK) {
    Error_Handler();
  }
  hsai_BlockA1.Instance = SAI1_Block_A;
  hsai_BlockA1.Init.AudioMode = SAI_MODEMASTER_TX;
  hsai_BlockA1.Init.Synchro = SAI_ASYNCHRONOUS;
  hsai_BlockA1.Init.OutputDrive = SAI_OUTPUTDRIVE_DISABLE;
  hsai_BlockA1.Init.NoDivider = SAI_MASTERDIVIDER_ENABLE;
  hsai_BlockA1.Init.FIFOThreshold = SAI_FIFOTHRESHOLD_EMPTY;
  hsai_BlockA1.Init.AudioFrequency = SAI_AUDIO_FREQUENCY_192K;
  hsai_BlockA1.Init.SynchroExt = SAI_SYNCEXT_DISABLE;
  hsai_BlockA1.Init.MonoStereoMode = SAI_STEREOMODE;
  hsai_BlockA1.Init.CompandingMode = SAI_NOCOMPANDING;
  hsai_BlockA1.Init.TriState = SAI_OUTPUT_NOTRELEASED;
  if (HAL_SAI_InitProtocol(&hsai_BlockA1, SAI_I2S_STANDARD,
                           SAI_PROTOCOL_DATASIZE_16BIT, 2) != HAL_OK) {
    Error_Handler();
  }
}

static void MX_SAI2_Init(void) {

  hsai_BlockA2.Instance = SAI2_Block_A;
  hsai_BlockA2.Init.Protocol = SAI_FREE_PROTOCOL;
  hsai_BlockA2.Init.AudioMode = SAI_MODEMASTER_TX;
  hsai_BlockA2.Init.DataSize = SAI_DATASIZE_8;
  hsai_BlockA2.Init.FirstBit = SAI_FIRSTBIT_MSB;
  hsai_BlockA2.Init.ClockStrobing = SAI_CLOCKSTROBING_FALLINGEDGE;
  hsai_BlockA2.Init.Synchro = SAI_ASYNCHRONOUS;
  hsai_BlockA2.Init.OutputDrive = SAI_OUTPUTDRIVE_DISABLE;
  hsai_BlockA2.Init.NoDivider = SAI_MASTERDIVIDER_ENABLE;
  hsai_BlockA2.Init.MckOverSampling = SAI_MCK_OVERSAMPLING_DISABLE;
  hsai_BlockA2.Init.FIFOThreshold = SAI_FIFOTHRESHOLD_EMPTY;
  hsai_BlockA2.Init.AudioFrequency = SAI_AUDIO_FREQUENCY_192K;
  hsai_BlockA2.Init.SynchroExt = SAI_SYNCEXT_DISABLE;
  hsai_BlockA2.Init.MonoStereoMode = SAI_STEREOMODE;
  hsai_BlockA2.Init.CompandingMode = SAI_NOCOMPANDING;
  hsai_BlockA2.Init.TriState = SAI_OUTPUT_NOTRELEASED;
  hsai_BlockA2.Init.PdmInit.Activation = DISABLE;
  hsai_BlockA2.Init.PdmInit.MicPairsNbr = 0;
  hsai_BlockA2.Init.PdmInit.ClockEnable = SAI_PDM_CLOCK1_ENABLE;
  hsai_BlockA2.FrameInit.FrameLength = 8;
  hsai_BlockA2.FrameInit.ActiveFrameLength = 1;
  hsai_BlockA2.FrameInit.FSDefinition = SAI_FS_STARTFRAME;
  hsai_BlockA2.FrameInit.FSPolarity = SAI_FS_ACTIVE_LOW;
  hsai_BlockA2.FrameInit.FSOffset = SAI_FS_FIRSTBIT;
  hsai_BlockA2.SlotInit.FirstBitOffset = 0;
  hsai_BlockA2.SlotInit.SlotSize = SAI_SLOTSIZE_DATASIZE;
  hsai_BlockA2.SlotInit.SlotNumber = 1;
  hsai_BlockA2.SlotInit.SlotActive = 0x00000000;
  if (HAL_SAI_Init(&hsai_BlockA2) != HAL_OK) {
    Error_Handler();
  }
}

static void MX_SPI2_Init(void) {

  /* SPI2 parameter configuration*/
  hspi2.Instance = SPI2;
  hspi2.Init.Mode = SPI_MODE_MASTER;
  hspi2.Init.Direction = SPI_DIRECTION_2LINES;
  hspi2.Init.DataSize = SPI_DATASIZE_8BIT;
  hspi2.Init.CLKPolarity = SPI_POLARITY_LOW;
  hspi2.Init.CLKPhase = SPI_PHASE_1EDGE;
  hspi2.Init.NSS = SPI_NSS_SOFT;
  hspi2.Init.BaudRatePrescaler = SPI_BAUDRATEPRESCALER_16;
  hspi2.Init.FirstBit = SPI_FIRSTBIT_MSB;
  hspi2.Init.TIMode = SPI_TIMODE_DISABLE;
  hspi2.Init.CRCCalculation = SPI_CRCCALCULATION_DISABLE;
  hspi2.Init.CRCPolynomial = 7;
  hspi2.Init.CRCLength = SPI_CRC_LENGTH_DATASIZE;
  hspi2.Init.NSSPMode = SPI_NSS_PULSE_ENABLE;
  if (HAL_SPI_Init(&hspi2) != HAL_OK) {
    Error_Handler();
  }
}

static void MX_SPI3_Init(void) {

  /* SPI3 parameter configuration*/
  hspi3.Instance = SPI3;
  hspi3.Init.Mode = SPI_MODE_MASTER;
  hspi3.Init.Direction = SPI_DIRECTION_2LINES;
  hspi3.Init.DataSize = SPI_DATASIZE_8BIT;
  hspi3.Init.CLKPolarity = SPI_POLARITY_LOW;
  hspi3.Init.CLKPhase = SPI_PHASE_1EDGE;
  hspi3.Init.NSS = SPI_NSS_SOFT;
  hspi3.Init.BaudRatePrescaler = SPI_BAUDRATEPRESCALER_2;
  hspi3.Init.FirstBit = SPI_FIRSTBIT_MSB;
  hspi3.Init.TIMode = SPI_TIMODE_DISABLE;
  hspi3.Init.CRCCalculation = SPI_CRCCALCULATION_DISABLE;
  hspi3.Init.CRCPolynomial = 7;
  hspi3.Init.CRCLength = SPI_CRC_LENGTH_DATASIZE;
  hspi3.Init.NSSPMode = SPI_NSS_PULSE_ENABLE;
  if (HAL_SPI_Init(&hspi3) != HAL_OK) {
    Error_Handler();
  }
}

static void MX_TIM1_Init(void) {

  TIM_MasterConfigTypeDef sMasterConfig = {0};
  TIMEx_BreakInputConfigTypeDef sBreakInputConfig = {0};
  TIM_OC_InitTypeDef sConfigOC = {0};
  TIM_BreakDeadTimeConfigTypeDef sBreakDeadTimeConfig = {0};

  htim1.Instance = TIM1;
  htim1.Init.Prescaler = 0;
  htim1.Init.CounterMode = TIM_COUNTERMODE_UP;
  htim1.Init.Period = 65535;
  htim1.Init.ClockDivision = TIM_CLOCKDIVISION_DIV1;
  htim1.Init.RepetitionCounter = 0;
  htim1.Init.AutoReloadPreload = TIM_AUTORELOAD_PRELOAD_DISABLE;
  if (HAL_TIM_PWM_Init(&htim1) != HAL_OK) {
    Error_Handler();
  }
  sMasterConfig.MasterOutputTrigger = TIM_TRGO_RESET;
  sMasterConfig.MasterOutputTrigger2 = TIM_TRGO2_RESET;
  sMasterConfig.MasterSlaveMode = TIM_MASTERSLAVEMODE_DISABLE;
  if (HAL_TIMEx_MasterConfigSynchronization(&htim1, &sMasterConfig) != HAL_OK) {
    Error_Handler();
  }
  sBreakInputConfig.Source = TIM_BREAKINPUTSOURCE_BKIN;
  sBreakInputConfig.Enable = TIM_BREAKINPUTSOURCE_ENABLE;
  sBreakInputConfig.Polarity = TIM_BREAKINPUTSOURCE_POLARITY_HIGH;
  if (HAL_TIMEx_ConfigBreakInput(&htim1, TIM_BREAKINPUT_BRK,
                                 &sBreakInputConfig) != HAL_OK) {
    Error_Handler();
  }
  if (HAL_TIMEx_ConfigBreakInput(&htim1, TIM_BREAKINPUT_BRK2,
                                 &sBreakInputConfig) != HAL_OK) {
    Error_Handler();
  }
  sConfigOC.OCMode = TIM_OCMODE_PWM1;
  sConfigOC.Pulse = 0;
  sConfigOC.OCPolarity = TIM_OCPOLARITY_HIGH;
  sConfigOC.OCNPolarity = TIM_OCNPOLARITY_HIGH;
  sConfigOC.OCFastMode = TIM_OCFAST_DISABLE;
  sConfigOC.OCIdleState = TIM_OCIDLESTATE_RESET;
  sConfigOC.OCNIdleState = TIM_OCNIDLESTATE_RESET;
  if (HAL_TIM_PWM_ConfigChannel(&htim1, &sConfigOC, TIM_CHANNEL_3) != HAL_OK) {
    Error_Handler();
  }
  sBreakDeadTimeConfig.OffStateRunMode = TIM_OSSR_ENABLE;
  sBreakDeadTimeConfig.OffStateIDLEMode = TIM_OSSI_ENABLE;
  sBreakDeadTimeConfig.LockLevel = TIM_LOCKLEVEL_OFF;
  sBreakDeadTimeConfig.DeadTime = 0;
  sBreakDeadTimeConfig.BreakState = TIM_BREAK_ENABLE;
  sBreakDeadTimeConfig.BreakPolarity = TIM_BREAKPOLARITY_HIGH;
  sBreakDeadTimeConfig.BreakFilter = 0;
  sBreakDeadTimeConfig.Break2State = TIM_BREAK2_ENABLE;
  sBreakDeadTimeConfig.Break2Polarity = TIM_BREAK2POLARITY_HIGH;
  sBreakDeadTimeConfig.Break2Filter = 0;
  sBreakDeadTimeConfig.AutomaticOutput = TIM_AUTOMATICOUTPUT_DISABLE;
  if (HAL_TIMEx_ConfigBreakDeadTime(&htim1, &sBreakDeadTimeConfig) != HAL_OK) {
    Error_Handler();
  }
  HAL_TIM_MspPostInit(&htim1);
}

static void MX_TIM2_Init(void) {

  TIM_MasterConfigTypeDef sMasterConfig = {0};
  TIM_OC_InitTypeDef sConfigOC = {0};

  htim2.Instance = TIM2;
  htim2.Init.Prescaler = 0;
  htim2.Init.CounterMode = TIM_COUNTERMODE_UP;
  htim2.Init.Period = 4294967295;
  htim2.Init.ClockDivision = TIM_CLOCKDIVISION_DIV1;
  htim2.Init.AutoReloadPreload = TIM_AUTORELOAD_PRELOAD_DISABLE;
  if (HAL_TIM_PWM_Init(&htim2) != HAL_OK) {
    Error_Handler();
  }
  sMasterConfig.MasterOutputTrigger = TIM_TRGO_RESET;
  sMasterConfig.MasterSlaveMode = TIM_MASTERSLAVEMODE_DISABLE;
  if (HAL_TIMEx_MasterConfigSynchronization(&htim2, &sMasterConfig) != HAL_OK) {
    Error_Handler();
  }
  sConfigOC.OCMode = TIM_OCMODE_PWM1;
  sConfigOC.Pulse = 0;
  sConfigOC.OCPolarity = TIM_OCPOLARITY_HIGH;
  sConfigOC.OCFastMode = TIM_OCFAST_DISABLE;
  if (HAL_TIM_PWM_ConfigChannel(&htim2, &sConfigOC, TIM_CHANNEL_1) != HAL_OK) {
    Error_Handler();
  }
  if (HAL_TIM_PWM_ConfigChannel(&htim2, &sConfigOC, TIM_CHANNEL_3) != HAL_OK) {
    Error_Handler();
  }
  HAL_TIM_MspPostInit(&htim2);
}

static void MX_TIM3_Init(void) {

  TIM_ClockConfigTypeDef sClockSourceConfig = {0};
  TIM_MasterConfigTypeDef sMasterConfig = {0};
  TIM_OC_InitTypeDef sConfigOC = {0};

  htim3.Instance = TIM3;
  htim3.Init.Prescaler = 0;
  htim3.Init.CounterMode = TIM_COUNTERMODE_UP;
  htim3.Init.Period = 65535;
  htim3.Init.ClockDivision = TIM_CLOCKDIVISION_DIV1;
  htim3.Init.AutoReloadPreload = TIM_AUTORELOAD_PRELOAD_DISABLE;
  if (HAL_TIM_Base_Init(&htim3) != HAL_OK) {
    Error_Handler();
  }
  sClockSourceConfig.ClockSource = TIM_CLOCKSOURCE_INTERNAL;
  if (HAL_TIM_ConfigClockSource(&htim3, &sClockSourceConfig) != HAL_OK) {
    Error_Handler();
  }
  if (HAL_TIM_PWM_Init(&htim3) != HAL_OK) {
    Error_Handler();
  }
  sMasterConfig.MasterOutputTrigger = TIM_TRGO_RESET;
  sMasterConfig.MasterSlaveMode = TIM_MASTERSLAVEMODE_DISABLE;
  if (HAL_TIMEx_MasterConfigSynchronization(&htim3, &sMasterConfig) != HAL_OK) {
    Error_Handler();
  }
  sConfigOC.OCMode = TIM_OCMODE_PWM1;
  sConfigOC.Pulse = 0;
  sConfigOC.OCPolarity = TIM_OCPOLARITY_HIGH;
  sConfigOC.OCFastMode = TIM_OCFAST_DISABLE;
  if (HAL_TIM_PWM_ConfigChannel(&htim3, &sConfigOC, TIM_CHANNEL_2) != HAL_OK) {
    Error_Handler();
  }
  if (HAL_TIM_PWM_ConfigChannel(&htim3, &sConfigOC, TIM_CHANNEL_3) != HAL_OK) {
    Error_Handler();
  }
  HAL_TIM_MspPostInit(&htim3);
}

static void MX_TIM4_Init(void) {

  TIM_MasterConfigTypeDef sMasterConfig = {0};
  TIM_OC_InitTypeDef sConfigOC = {0};

  htim4.Instance = TIM4;
  htim4.Init.Prescaler = 0;
  htim4.Init.CounterMode = TIM_COUNTERMODE_UP;
  htim4.Init.Period = 65535;
  htim4.Init.ClockDivision = TIM_CLOCKDIVISION_DIV1;
  htim4.Init.AutoReloadPreload = TIM_AUTORELOAD_PRELOAD_DISABLE;
  if (HAL_TIM_PWM_Init(&htim4) != HAL_OK) {
    Error_Handler();
  }
  sMasterConfig.MasterOutputTrigger = TIM_TRGO_RESET;
  sMasterConfig.MasterSlaveMode = TIM_MASTERSLAVEMODE_DISABLE;
  if (HAL_TIMEx_MasterConfigSynchronization(&htim4, &sMasterConfig) != HAL_OK) {
    Error_Handler();
  }
  sConfigOC.OCMode = TIM_OCMODE_PWM1;
  sConfigOC.Pulse = 0;
  sConfigOC.OCPolarity = TIM_OCPOLARITY_HIGH;
  sConfigOC.OCFastMode = TIM_OCFAST_DISABLE;
  if (HAL_TIM_PWM_ConfigChannel(&htim4, &sConfigOC, TIM_CHANNEL_4) != HAL_OK) {
    Error_Handler();
  }
  HAL_TIM_MspPostInit(&htim4);
}

static void MX_TIM15_Init(void) {

  TIM_MasterConfigTypeDef sMasterConfig = {0};
  TIM_OC_InitTypeDef sConfigOC = {0};
  TIM_BreakDeadTimeConfigTypeDef sBreakDeadTimeConfig = {0};

  htim15.Instance = TIM15;
  htim15.Init.Prescaler = 0;
  htim15.Init.CounterMode = TIM_COUNTERMODE_UP;
  htim15.Init.Period = 65535;
  htim15.Init.ClockDivision = TIM_CLOCKDIVISION_DIV1;
  htim15.Init.RepetitionCounter = 0;
  htim15.Init.AutoReloadPreload = TIM_AUTORELOAD_PRELOAD_DISABLE;
  if (HAL_TIM_PWM_Init(&htim15) != HAL_OK) {
    Error_Handler();
  }
  sMasterConfig.MasterOutputTrigger = TIM_TRGO_RESET;
  sMasterConfig.MasterSlaveMode = TIM_MASTERSLAVEMODE_DISABLE;
  if (HAL_TIMEx_MasterConfigSynchronization(&htim15, &sMasterConfig) !=
      HAL_OK) {
    Error_Handler();
  }
  sConfigOC.OCMode = TIM_OCMODE_PWM1;
  sConfigOC.Pulse = 0;
  sConfigOC.OCPolarity = TIM_OCPOLARITY_HIGH;
  sConfigOC.OCNPolarity = TIM_OCNPOLARITY_HIGH;
  sConfigOC.OCFastMode = TIM_OCFAST_DISABLE;
  sConfigOC.OCIdleState = TIM_OCIDLESTATE_RESET;
  sConfigOC.OCNIdleState = TIM_OCNIDLESTATE_RESET;
  if (HAL_TIM_PWM_ConfigChannel(&htim15, &sConfigOC, TIM_CHANNEL_1) != HAL_OK) {
    Error_Handler();
  }
  sBreakDeadTimeConfig.OffStateRunMode = TIM_OSSR_DISABLE;
  sBreakDeadTimeConfig.OffStateIDLEMode = TIM_OSSI_DISABLE;
  sBreakDeadTimeConfig.LockLevel = TIM_LOCKLEVEL_OFF;
  sBreakDeadTimeConfig.DeadTime = 0;
  sBreakDeadTimeConfig.BreakState = TIM_BREAK_DISABLE;
  sBreakDeadTimeConfig.BreakPolarity = TIM_BREAKPOLARITY_HIGH;
  sBreakDeadTimeConfig.AutomaticOutput = TIM_AUTOMATICOUTPUT_DISABLE;
  if (HAL_TIMEx_ConfigBreakDeadTime(&htim15, &sBreakDeadTimeConfig) != HAL_OK) {
    Error_Handler();
  }
  HAL_TIM_MspPostInit(&htim15);
}

static void MX_TIM17_Init(void) {

  TIM_OC_InitTypeDef sConfigOC = {0};
  TIM_BreakDeadTimeConfigTypeDef sBreakDeadTimeConfig = {0};

  htim17.Instance = TIM17;
  htim17.Init.Prescaler = 2441;
  htim17.Init.CounterMode = TIM_COUNTERMODE_UP;
  htim17.Init.Period = 65535;
  htim17.Init.ClockDivision = TIM_CLOCKDIVISION_DIV1;
  htim17.Init.RepetitionCounter = 0;
  htim17.Init.AutoReloadPreload = TIM_AUTORELOAD_PRELOAD_DISABLE;
  if (HAL_TIM_Base_Init(&htim17) != HAL_OK) {
    Error_Handler();
  }
  if (HAL_TIM_OC_Init(&htim17) != HAL_OK) {
    Error_Handler();
  }
  sConfigOC.OCMode = TIM_OCMODE_TIMING;
  sConfigOC.Pulse = 0;
  sConfigOC.OCPolarity = TIM_OCPOLARITY_HIGH;
  sConfigOC.OCNPolarity = TIM_OCNPOLARITY_HIGH;
  sConfigOC.OCFastMode = TIM_OCFAST_DISABLE;
  sConfigOC.OCIdleState = TIM_OCIDLESTATE_RESET;
  sConfigOC.OCNIdleState = TIM_OCNIDLESTATE_RESET;
  if (HAL_TIM_OC_ConfigChannel(&htim17, &sConfigOC, TIM_CHANNEL_1) != HAL_OK) {
    Error_Handler();
  }
  sBreakDeadTimeConfig.OffStateRunMode = TIM_OSSR_DISABLE;
  sBreakDeadTimeConfig.OffStateIDLEMode = TIM_OSSI_DISABLE;
  sBreakDeadTimeConfig.LockLevel = TIM_LOCKLEVEL_OFF;
  sBreakDeadTimeConfig.DeadTime = 0;
  sBreakDeadTimeConfig.BreakState = TIM_BREAK_DISABLE;
  sBreakDeadTimeConfig.BreakPolarity = TIM_BREAKPOLARITY_HIGH;
  sBreakDeadTimeConfig.AutomaticOutput = TIM_AUTOMATICOUTPUT_DISABLE;
  if (HAL_TIMEx_ConfigBreakDeadTime(&htim17, &sBreakDeadTimeConfig) != HAL_OK) {
    Error_Handler();
  }
}

static void MX_USB_OTG_FS_USB_Init(void) {

}

static void MX_GPIO_Init(void) {
  GPIO_InitTypeDef GPIO_InitStruct = {0};

  /* GPIO Ports Clock Enable */
  __HAL_RCC_GPIOE_CLK_ENABLE();
  __HAL_RCC_GPIOC_CLK_ENABLE();
  __HAL_RCC_GPIOF_CLK_ENABLE();
  __HAL_RCC_GPIOH_CLK_ENABLE();
  __HAL_RCC_GPIOA_CLK_ENABLE();
  __HAL_RCC_GPIOB_CLK_ENABLE();
  __HAL_RCC_GPIOD_CLK_ENABLE();
  __HAL_RCC_GPIOG_CLK_ENABLE();
  HAL_PWREx_EnableVddIO2();

  /*Configure GPIO pin Output Level */
  HAL_GPIO_WritePin(GPIOF, GPIO_PIN_13 | GPIO_PIN_14, GPIO_PIN_RESET);

  /*Configure GPIO pin Output Level */
  HAL_GPIO_WritePin(
      GPIOE, GPIO_PIN_7 | GPIO_PIN_8 | GPIO_PIN_9 | GPIO_PIN_10 | GPIO_PIN_11,
      GPIO_PIN_RESET);

  /*Configure GPIO pin Output Level */
  HAL_GPIO_WritePin(GPIOD, GPIO_PIN_0, GPIO_PIN_SET);

  /*Configure GPIO pin : PF5 */
  GPIO_InitStruct.Pin = GPIO_PIN_5;
  GPIO_InitStruct.Mode = GPIO_MODE_IT_RISING;
  GPIO_InitStruct.Pull = GPIO_NOPULL;
  HAL_GPIO_Init(GPIOF, &GPIO_InitStruct);

  /*Configure GPIO pin : PA4 */
  GPIO_InitStruct.Pin = GPIO_PIN_4;
  GPIO_InitStruct.Mode = GPIO_MODE_AF_PP;
  GPIO_InitStruct.Pull = GPIO_NOPULL;
  GPIO_InitStruct.Speed = GPIO_SPEED_FREQ_VERY_HIGH;
  GPIO_InitStruct.Alternate = GPIO_AF5_SPI1;
  HAL_GPIO_Init(GPIOA, &GPIO_InitStruct);

  /*Configure GPIO pins : PA5 PA6 PA7 */
  GPIO_InitStruct.Pin = GPIO_PIN_5 | GPIO_PIN_6 | GPIO_PIN_7;
  GPIO_InitStruct.Mode = GPIO_MODE_INPUT;
  GPIO_InitStruct.Pull = GPIO_PULLUP;
  HAL_GPIO_Init(GPIOA, &GPIO_InitStruct);

  /*Configure GPIO pins : PF13 PF14 */
  GPIO_InitStruct.Pin = GPIO_PIN_13 | GPIO_PIN_14;
  GPIO_InitStruct.Mode = GPIO_MODE_OUTPUT_OD;
  GPIO_InitStruct.Pull = GPIO_NOPULL;
  GPIO_InitStruct.Speed = GPIO_SPEED_FREQ_LOW;
  HAL_GPIO_Init(GPIOF, &GPIO_InitStruct);

  /*Configure GPIO pins : PE7 PE8 PE10 */
  GPIO_InitStruct.Pin = GPIO_PIN_7 | GPIO_PIN_8 | GPIO_PIN_10;
  GPIO_InitStruct.Mode = GPIO_MODE_OUTPUT_PP;
  GPIO_InitStruct.Pull = GPIO_PULLUP;
  GPIO_InitStruct.Speed = GPIO_SPEED_FREQ_LOW;
  HAL_GPIO_Init(GPIOE, &GPIO_InitStruct);

  /*Configure GPIO pins : PE9 PE11 */
  GPIO_InitStruct.Pin = GPIO_PIN_9 | GPIO_PIN_11;
  GPIO_InitStruct.Mode = GPIO_MODE_OUTPUT_OD;
  GPIO_InitStruct.Pull = GPIO_NOPULL;
  GPIO_InitStruct.Speed = GPIO_SPEED_FREQ_LOW;
  HAL_GPIO_Init(GPIOE, &GPIO_InitStruct);

  /*Configure GPIO pin : PD14 */
  GPIO_InitStruct.Pin = GPIO_PIN_14;
  GPIO_InitStruct.Mode = GPIO_MODE_IT_FALLING;
  GPIO_InitStruct.Pull = GPIO_PULLUP;
  HAL_GPIO_Init(GPIOD, &GPIO_InitStruct);

  /*Configure GPIO pin : PC9 */
  GPIO_InitStruct.Pin = GPIO_PIN_9;
  GPIO_InitStruct.Mode = GPIO_MODE_AF_PP;
  GPIO_InitStruct.Pull = GPIO_NOPULL;
  GPIO_InitStruct.Speed = GPIO_SPEED_FREQ_VERY_HIGH;
  GPIO_InitStruct.Alternate = GPIO_AF12_SDMMC1;
  HAL_GPIO_Init(GPIOC, &GPIO_InitStruct);

  /*Configure GPIO pins : PA8 PA10 PA11 PA12 */
  GPIO_InitStruct.Pin = GPIO_PIN_8 | GPIO_PIN_10 | GPIO_PIN_11 | GPIO_PIN_12;
  GPIO_InitStruct.Mode = GPIO_MODE_AF_PP;
  GPIO_InitStruct.Pull = GPIO_NOPULL;
  GPIO_InitStruct.Speed = GPIO_SPEED_FREQ_VERY_HIGH;
  GPIO_InitStruct.Alternate = GPIO_AF10_OTG_FS;
  HAL_GPIO_Init(GPIOA, &GPIO_InitStruct);

  /*Configure GPIO pin : PA9 */
  GPIO_InitStruct.Pin = GPIO_PIN_9;
  GPIO_InitStruct.Mode = GPIO_MODE_INPUT;
  GPIO_InitStruct.Pull = GPIO_NOPULL;
  HAL_GPIO_Init(GPIOA, &GPIO_InitStruct);

  /*Configure GPIO pin : PD0 */
  GPIO_InitStruct.Pin = GPIO_PIN_0;
  GPIO_InitStruct.Mode = GPIO_MODE_OUTPUT_PP;
  GPIO_InitStruct.Pull = GPIO_NOPULL;
  GPIO_InitStruct.Speed = GPIO_SPEED_FREQ_LOW;
  HAL_GPIO_Init(GPIOD, &GPIO_InitStruct);

  /*Configure GPIO pin : PD2 */
  GPIO_InitStruct.Pin = GPIO_PIN_2;
  GPIO_InitStruct.Mode = GPIO_MODE_AF_PP;
  GPIO_InitStruct.Pull = GPIO_NOPULL;
  GPIO_InitStruct.Speed = GPIO_SPEED_FREQ_VERY_HIGH;
  GPIO_InitStruct.Alternate = GPIO_AF12_SDMMC1;
  HAL_GPIO_Init(GPIOD, &GPIO_InitStruct);

  /* EXTI interrupt init*/
  HAL_NVIC_SetPriority(EXTI9_5_IRQn, 0, 0);
  HAL_NVIC_EnableIRQ(EXTI9_5_IRQn);

  HAL_NVIC_SetPriority(EXTI15_10_IRQn, 0, 0);
  HAL_NVIC_EnableIRQ(EXTI15_10_IRQn);

}

/* USER CODE BEGIN 4 */

void HAL_TIM_PeriodElapsedCallback(TIM_HandleTypeDef *htim) {
  // check which version of the timer triggered this callback and toggle LED
  if (htim == &htim17) {
    DISPLAY_TIMER_TRIGGERED = 1;
  }
}

#ifdef __GNUC__
#define PUTCHAR_PROTOTYPE int __io_putchar(int ch)
#else
#define PUTCHAR_PROTOTYPE int fputc(int ch, FILE *f)
#endif /* __GNUC__ */
PUTCHAR_PROTOTYPE {
  HAL_UART_Transmit(&hlpuart1, (uint8_t *)&ch, 1, 0xFFFF);
  return ch;
}

/* USER CODE END 4 */

void Error_Handler(void) {
  __disable_irq();
  while (1) {
  }
}

#ifdef USE_FULL_ASSERT
/**
 * @brief  Reports the name of the source file and the source line number
 *         where the assert_param error has occurred.
 * @param  file: pointer to the source file name
 * @param  line: assert_param error line source number
 * @retval None
 */
void assert_failed(uint8_t *file, uint32_t line) {
  /* USER CODE BEGIN 6 */
  /* User can add his own implementation to report the file name and line
     number, ex: printf("Wrong parameters value: file %s on line %d\r\n", file,
     line) */
  /* USER CODE END 6 */
}
#endif /* USE_FULL_ASSERT */
